# STM32WBA55 register map
File version: 1.0
CPU: CM33 r0p1, little endian, MPU, FPU, 4 interrupt priority bits
Registers are 32-bit, read-write, reset 0x0 unless marked. A register's access mark holds for its fields unless they carry their own. Offsets are from the block's base; [hi:lo] are bit positions; {n}, {i} and the like mark numbered series; 'fields as' and 'values as' point back to an identical list.

## HASH — HASH register block
Base 0x420C0400
Same registers: SEC_HASH 0x520C0400
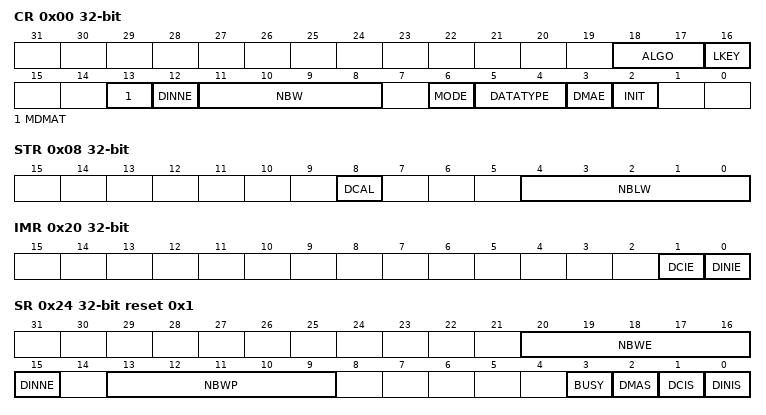
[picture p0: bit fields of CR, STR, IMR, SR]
0x00 CR — HASH control register
  [18:17] ALGO — Algorithm selection These bits select the hash algorithm. This selection is only taken into account when the INIT bit is set. Changing this bitfield during a computation has no effect. When ALGO bitfield is updated and INIT bit is set, NBWE in HASH_SR is automatically updated to 0x11.
  [16] LKEY — Long key selection This bit selects between short key (less than or equal 64 bytes) or long key ( 64 bytes) in HMAC mode. This selection is only taken into account when the INIT and MODE bits are both set. Changing this bit during a computation has no effect.
  [13] MDMAT — Multiple DMA transfers This bit is set when hashing large files when multiple DMA transfers are needed.
  [12] DINNE ro — DIN not empty Refer to DINNE bit of HASH_SR for the description. This bit is read-only.
  [11:8] NBW ro — Number of words already pushed Refer to NBWP[3:0] bitfield of HASH_SR for the description. This bitfield is read-only.
  [6] MODE — Mode selection This bit selects the HASH or HMAC mode for the selected algorithm: This selection is only taken into account when the INIT bit is set. Changing this bit during a computation has no effect.
  [5:4] DATATYPE — Data type selection Defines the format of the data entered into the HASH_DIN register:
  [3] DMAE — DMA enable After this bit is set it is cleared by hardware while the last data of the message is written into the hash processor. Setting this bit to 0 while a DMA transfer is ongoing is not aborting this current transfer. Instead, the DMA interface of the IP remains internally enabled until the transfer is completed or INIT is written to 1. Setting INIT bit to 1 does not clear DMAE bit.
  [2] INIT — Initialize message digest calculation Writing this bit to 1 resets the hash processor core, so that the HASH is ready to compute the message digest of a new message. Writing this bit to 0 has no effect. Reading this bit always return 0.
0x04 DIN wo — HASH data input register
  [31:0] DATAIN — Data input Writing this register pushes the current register content into the IN FIFO, and the register takes the new value presented on the AHB databus. Reading this register returns zeros.
0x08 STR — HASH start register
  [8] DCAL — Digest calculation Writing this bit to 1 starts the message padding, using the previously written value of NBLW[4:0], and starts the calculation of the final message digest with all data words written to the input FIFO since the INIT bit was last written to 1. Reading this bit returns 0.
  [4:0] NBLW — Number of valid bits in the last word When the last word of the message bit string is written in HASH_DIN register, the hash processor takes only the valid bits specified as below, after internal data swapping: ... The above mechanism is valid only if DCAL = 0. If NBLW[4:0] bitfield is written while DCAL is set to 1, the NBLW[4:0] bitfield remains unchanged. In other words it is not possible to configure NBLW[4:0] and set DCAL at the same time. Reading NBLW[4:0] bitfield returns the last value written to NBLW[4:0].
{0xC+4i} HRA{i} ro (i=0..4) — HASH aliased digest register {i}
  [31:0] H{i} — Hash data x Refer to Section 25.7.4: HASH digest registers introduction.
0x20 IMR — HASH interrupt enable register
  [1] DCIE — Digest calculation completion interrupt enable
  [0] DINIE — Data input interrupt enable
0x24 SR reset 0x1 — HASH status register
  [20:16] NBWE ro — Number of words expected This bitfield reflects the number of words in the message that must be pushed into the FIFO to trigger a partial computation. NBWE is decremented by 1 when a write access is performed to the HASH_DIN register. NBWE is set to the expected block size +1 in words (0x11) when INIT bit is set in HASH_CR, and it is set to the expected block size when partial digest calculation ends.
  [15] DINNE ro — DIN not empty This bit is set when the HASH_DIN register holds valid data (that is after being written at least once). It is cleared when either the INIT bit (initialization) or the DCAL bit (completion of the previous message processing) is written to 1.
  [13:9] NBWP ro — Number of words already pushed This bitfield is the exact number of words in the message that have already been pushed into the FIFO. NBWP is incremented by one when a write access is performed to the HASH_DIN register. When a digest calculation starts, NBWP is updated to NBWP- block size (in words), and NBWP goes to zero when the INIT bit is written to 1.
  [3] BUSY ro — Busy bit
  [2] DMAS ro — DMA Status This bit provides information on the DMA interface activity. It is set with DMAE and cleared when DMAE = 0 and no DMA transfer is ongoing. No interrupt is associated with this bit.
  [1] DCIS — Digest calculation completion interrupt status This bit is set by hardware when a digest becomes ready (the whole message has been processed). It is cleared by writing it to 0 or by writing the INIT bit to 1 in the HASH_CR register.
  [0] DINIS — Data input interrupt status This bit is set by hardware when the FIFO is ready to get a new block (16 locations are free). It is cleared by writing it to 0 or by writing the HASH_DIN register. When DINIS=0, HASH_CSRx registers reads as zero.
{0xF8+4i} CSR{i} (i=0..53) — HASH context swap register {i}
  [31:0] CS{i} — Context swap x Refer to Section 25.7.7: HASH context swap registers introduction.
{0x310+4i} HR{i} ro (i=0..4) — HASH digest register {i}
  fields as HRA0
{0x310+4i} HR{i} ro (i=5..7) — HASH supplementary digest register {i}
  fields as HRA0
